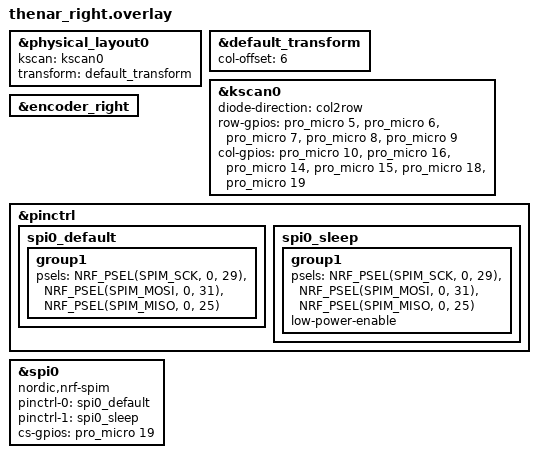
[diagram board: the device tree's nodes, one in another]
#include "thenar.dtsi"

&physical_layout0 {
    kscan = <&kscan0>;
    transform = <&default_transform>;
};

// Right half's matrix positions live in columns 6..11 of the 12-wide map.
&default_transform {
    col-offset = <6>;
};

&kscan0 {
    diode-direction = "col2row";

    // SAME pin lists as the left half's drive side: the halves are the
    // same copper, and the down-side jumpers make the same MCU pins hit
    // the same nets on both. (The old lists assumed mirrored pins - a
    // never-tested port bug that transposed+reversed the whole matrix.)
    row-gpios
        = <&pro_micro 5 (GPIO_ACTIVE_HIGH | GPIO_PULL_DOWN)>  // col0 (num)
        , <&pro_micro 6 (GPIO_ACTIVE_HIGH | GPIO_PULL_DOWN)>  // col1 (top)
        , <&pro_micro 7 (GPIO_ACTIVE_HIGH | GPIO_PULL_DOWN)>  // col2 (home)
        , <&pro_micro 8 (GPIO_ACTIVE_HIGH | GPIO_PULL_DOWN)>  // col3 (bottom)
        , <&pro_micro 9 (GPIO_ACTIVE_HIGH | GPIO_PULL_DOWN)>  // col4 (mod + thumb + scrollwheel)
        ;

    // Left's sense list REVERSED (inner-first): with col-offset 6, ZMK
    // col 6 must be the visually-leftmost key of this half = the inner
    // column = net row5. This is what mirrors the half in the keymap.
    col-gpios
        = <&pro_micro 10 GPIO_ACTIVE_HIGH>  // row5 (inner)
        , <&pro_micro 16 GPIO_ACTIVE_HIGH>  // row4 (index)
        , <&pro_micro 14 GPIO_ACTIVE_HIGH>  // row3 (middle)
        , <&pro_micro 15 GPIO_ACTIVE_HIGH>  // row2 (ring)
        , <&pro_micro 18 GPIO_ACTIVE_HIGH>  // row1 (pinky)
        , <&pro_micro 19 GPIO_ACTIVE_HIGH>  // row0 (outer)
        ;
};

&encoder_right {
    status = "okay";
};

&pinctrl {
    spi0_default: spi0_default {
        group1 {
            psels = <NRF_PSEL(SPIM_SCK, 0, 29)>,
                <NRF_PSEL(SPIM_MOSI, 0, 31)>,
                <NRF_PSEL(SPIM_MISO, 0, 25)>;
        };
    };
    spi0_sleep: spi0_sleep {
        group1 {
            psels = <NRF_PSEL(SPIM_SCK, 0, 29)>,
                <NRF_PSEL(SPIM_MOSI, 0, 31)>,
                <NRF_PSEL(SPIM_MISO, 0, 25)>;
            low-power-enable;
        };
    };
};

nice_view_spi: &spi0 {
    compatible = "nordic,nrf-spim";
    pinctrl-0 = <&spi0_default>;
    pinctrl-1 = <&spi0_sleep>;
    pinctrl-names = "default", "sleep";
    cs-gpios = <&pro_micro 19 GPIO_ACTIVE_HIGH>;
};
